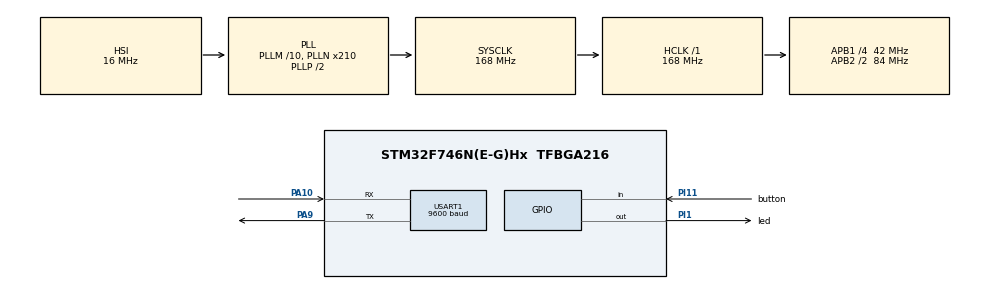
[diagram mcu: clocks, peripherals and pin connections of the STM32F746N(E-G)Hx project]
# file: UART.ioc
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Mcu.Family=STM32F7
Mcu.Name=STM32F746N(E-G)Hx
Mcu.Package=TFBGA216
NVIC.PriorityGroup=NVIC_PRIORITYGROUP_4
PA10.Mode=Asynchronous
PA10.Signal=USART1_RX
PA9.Mode=Asynchronous
PA9.Signal=USART1_TX
PI1.GPIO_Label=led
PI1.Signal=GPIO_Output
PI11.GPIO_Label=button
PI11.Signal=GPIO_Input
ProjectManager.HeapSize=0x200
ProjectManager.StackSize=0x400
ProjectManager.TargetToolchain=SW4STM32
RCC.AHBFreq_Value=168000000
RCC.APB1CLKDivider=RCC_HCLK_DIV4
RCC.APB1Freq_Value=42000000
RCC.APB1TimFreq_Value=84000000
RCC.APB2CLKDivider=RCC_HCLK_DIV2
RCC.APB2Freq_Value=84000000
RCC.APB2TimFreq_Value=168000000
RCC.CortexFreq_Value=168000000
RCC.HCLKFreq_Value=168000000
RCC.HSE_VALUE=25000000
RCC.HSI_VALUE=16000000
RCC.LSE_VALUE=32768
RCC.PLLM=10
RCC.PLLN=210
RCC.PLLSourceVirtual=RCC_PLLSOURCE_HSI
RCC.SYSCLKFreq_VALUE=168000000
RCC.SYSCLKSource=RCC_SYSCLKSOURCE_PLLCLK
RCC.USBFreq_Value=168000000
RCC.VCOOutputFreq_Value=336000000
USART1.BaudRate=9600
USART1.WordLength=UART_WORDLENGTH_8B
board=STM32F746G-DISCO

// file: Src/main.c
/**
  ******************************************************************************
  * File Name          : main.c
  * Description        : Main program body
  ******************************************************************************
  *
  * COPYRIGHT(c) 2016 STMicroelectronics
  *
  * Redistribution and use in source and binary forms, with or without modification,
  * are permitted provided that the following conditions are met:
  *   1. Redistributions of source code must retain the above copyright notice,
  *      this list of conditions and the following disclaimer.
  *   2. Redistributions in binary form must reproduce the above copyright notice,
  *      this list of conditions and the following disclaimer in the documentation
  *      and/or other materials provided with the distribution.
  *   3. Neither the name of STMicroelectronics nor the names of its contributors
  *      may be used to endorse or promote products derived from this software
  *      without specific prior written permission.
  *
  * THIS SOFTWARE IS PROVIDED BY THE COPYRIGHT HOLDERS AND CONTRIBUTORS "AS IS"
  * AND ANY EXPRESS OR IMPLIED WARRANTIES, INCLUDING, BUT NOT LIMITED TO, THE
  * IMPLIED WARRANTIES OF MERCHANTABILITY AND FITNESS FOR A PARTICULAR PURPOSE ARE
  * DISCLAIMED. IN NO EVENT SHALL THE COPYRIGHT HOLDER OR CONTRIBUTORS BE LIABLE
  * FOR ANY DIRECT, INDIRECT, INCIDENTAL, SPECIAL, EXEMPLARY, OR CONSEQUENTIAL
  * DAMAGES (INCLUDING, BUT NOT LIMITED TO, PROCUREMENT OF SUBSTITUTE GOODS OR
  * SERVICES; LOSS OF USE, DATA, OR PROFITS; OR BUSINESS INTERRUPTION) HOWEVER
  * CAUSED AND ON ANY THEORY OF LIABILITY, WHETHER IN CONTRACT, STRICT LIABILITY,
  * OR TORT (INCLUDING NEGLIGENCE OR OTHERWISE) ARISING IN ANY WAY OUT OF THE USE
  * OF THIS SOFTWARE, EVEN IF ADVISED OF THE POSSIBILITY OF SUCH DAMAGE.
  *
  ******************************************************************************
  */
#include "main.h"
#include "stm32f7xx_hal.h"

UART_HandleTypeDef huart1;

/* USER CODE BEGIN PV */
/* Private variables ---------------------------------------------------------*/

/* USER CODE END PV */

void SystemClock_Config(void);
void Error_Handler(void);
static void MX_GPIO_Init(void);
static void MX_USART1_UART_Init(void);

/* USER CODE BEGIN PFP */
/* Private function prototypes -----------------------------------------------*/

/* USER CODE END PFP */

int main(void)
{

  /* MCU Configuration----------------------------------------------------------*/

  /* Reset of all peripherals, Initializes the Flash interface and the Systick. */
  HAL_Init();

  /* Configure the system clock */
  SystemClock_Config();

  /* Initialize all configured peripherals */
  MX_GPIO_Init();
  MX_USART1_UART_Init();

  /* Infinite loop */
  while (1)
  {

  /* USER CODE BEGIN 3 */
	  char *boodschap = "TEST\n\r";
	  if(HAL_GPIO_ReadPin(button_GPIO_Port, button_Pin))
	  {
		  HAL_UART_Transmit(&huart1, (uint8_t*)boodschap, strlen(boodschap), 0XFFFF);
		  HAL_GPIO_WritePin(led_GPIO_Port, led_Pin, GPIO_PIN_SET);
	  }
	  else
	  {
		  HAL_GPIO_WritePin(led_GPIO_Port, led_Pin, GPIO_PIN_RESET);
	  }

  }
  /* USER CODE END 3 */

}

/** System Clock Configuration
*/
void SystemClock_Config(void)
{

  RCC_OscInitTypeDef RCC_OscInitStruct;
  RCC_ClkInitTypeDef RCC_ClkInitStruct;
  RCC_PeriphCLKInitTypeDef PeriphClkInitStruct;

    /**Configure the main internal regulator output voltage
    */
  __HAL_RCC_PWR_CLK_ENABLE();

  __HAL_PWR_VOLTAGESCALING_CONFIG(PWR_REGULATOR_VOLTAGE_SCALE2);

    /**Initializes the CPU, AHB and APB busses clocks
    */
  RCC_OscInitStruct.OscillatorType = RCC_OSCILLATORTYPE_HSI;
  RCC_OscInitStruct.HSIState = RCC_HSI_ON;
  RCC_OscInitStruct.HSICalibrationValue = 16;
  RCC_OscInitStruct.PLL.PLLState = RCC_PLL_ON;
  RCC_OscInitStruct.PLL.PLLSource = RCC_PLLSOURCE_HSI;
  RCC_OscInitStruct.PLL.PLLM = 10;
  RCC_OscInitStruct.PLL.PLLN = 210;
  RCC_OscInitStruct.PLL.PLLP = RCC_PLLP_DIV2;
  RCC_OscInitStruct.PLL.PLLQ = 2;
  if (HAL_RCC_OscConfig(&RCC_OscInitStruct) != HAL_OK)
  {
    Error_Handler();
  }

    /**Initializes the CPU, AHB and APB busses clocks
    */
  RCC_ClkInitStruct.ClockType = RCC_CLOCKTYPE_HCLK|RCC_CLOCKTYPE_SYSCLK
                              |RCC_CLOCKTYPE_PCLK1|RCC_CLOCKTYPE_PCLK2;
  RCC_ClkInitStruct.SYSCLKSource = RCC_SYSCLKSOURCE_PLLCLK;
  RCC_ClkInitStruct.AHBCLKDivider = RCC_SYSCLK_DIV1;
  RCC_ClkInitStruct.APB1CLKDivider = RCC_HCLK_DIV4;
  RCC_ClkInitStruct.APB2CLKDivider = RCC_HCLK_DIV2;

  if (HAL_RCC_ClockConfig(&RCC_ClkInitStruct, FLASH_LATENCY_5) != HAL_OK)
  {
    Error_Handler();
  }

  PeriphClkInitStruct.PeriphClockSelection = RCC_PERIPHCLK_USART1;
  PeriphClkInitStruct.Usart1ClockSelection = RCC_USART1CLKSOURCE_PCLK2;
  if (HAL_RCCEx_PeriphCLKConfig(&PeriphClkInitStruct) != HAL_OK)
  {
    Error_Handler();
  }

    /**Configure the Systick interrupt time
    */
  HAL_SYSTICK_Config(HAL_RCC_GetHCLKFreq()/1000);

    /**Configure the Systick
    */
  HAL_SYSTICK_CLKSourceConfig(SYSTICK_CLKSOURCE_HCLK);

  /* SysTick_IRQn interrupt configuration */
  HAL_NVIC_SetPriority(SysTick_IRQn, 0, 0);
}

/* USART1 init function */
static void MX_USART1_UART_Init(void)
{

  huart1.Instance = USART1;
  huart1.Init.BaudRate = 9600;
  huart1.Init.WordLength = UART_WORDLENGTH_8B;
  huart1.Init.StopBits = UART_STOPBITS_1;
  huart1.Init.Parity = UART_PARITY_NONE;
  huart1.Init.Mode = UART_MODE_TX_RX;
  huart1.Init.HwFlowCtl = UART_HWCONTROL_NONE;
  huart1.Init.OverSampling = UART_OVERSAMPLING_16;
  huart1.Init.OneBitSampling = UART_ONE_BIT_SAMPLE_DISABLE;
  huart1.AdvancedInit.AdvFeatureInit = UART_ADVFEATURE_NO_INIT;
  if (HAL_UART_Init(&huart1) != HAL_OK)
  {
    Error_Handler();
  }

}

/** Configure pins as
        * Analog
        * Input
        * Output
        * EVENT_OUT
        * EXTI
*/
static void MX_GPIO_Init(void)
{

  GPIO_InitTypeDef GPIO_InitStruct;

  /* GPIO Ports Clock Enable */
  __HAL_RCC_GPIOI_CLK_ENABLE();
  __HAL_RCC_GPIOA_CLK_ENABLE();

  /*Configure GPIO pin Output Level */
  HAL_GPIO_WritePin(led_GPIO_Port, led_Pin, GPIO_PIN_RESET);

  /*Configure GPIO pin : led_Pin */
  GPIO_InitStruct.Pin = led_Pin;
  GPIO_InitStruct.Mode = GPIO_MODE_OUTPUT_PP;
  GPIO_InitStruct.Pull = GPIO_NOPULL;
  GPIO_InitStruct.Speed = GPIO_SPEED_FREQ_LOW;
  HAL_GPIO_Init(led_GPIO_Port, &GPIO_InitStruct);

  /*Configure GPIO pin : button_Pin */
  GPIO_InitStruct.Pin = button_Pin;
  GPIO_InitStruct.Mode = GPIO_MODE_INPUT;
  GPIO_InitStruct.Pull = GPIO_NOPULL;
  HAL_GPIO_Init(button_GPIO_Port, &GPIO_InitStruct);

}

void Error_Handler(void)
{
  while(1)
  {
  }
}

/************************ (C) COPYRIGHT STMicroelectronics *****END OF FILE****/
